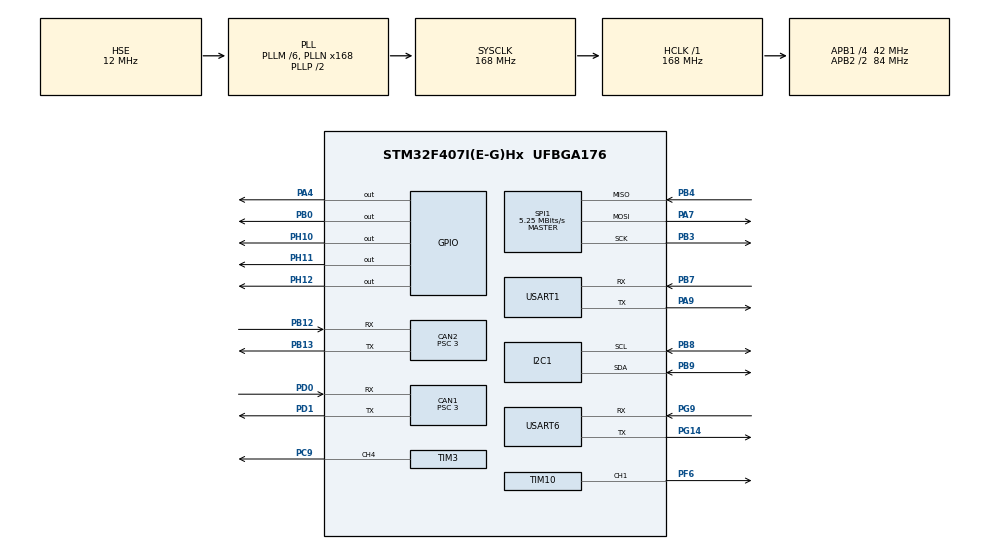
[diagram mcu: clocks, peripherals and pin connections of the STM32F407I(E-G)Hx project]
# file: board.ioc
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CAN1.ABOM=ENABLE
CAN1.BS1=CAN_BS1_10TQ
CAN1.BS2=CAN_BS2_3TQ
CAN1.CalculateBaudRate=1000000
CAN1.CalculateTimeBit=1000
CAN1.CalculateTimeQuantum=71.42857142857143
CAN1.Prescaler=3
CAN2.ABOM=ENABLE
CAN2.BS1=CAN_BS1_10TQ
CAN2.BS2=CAN_BS2_3TQ
CAN2.CalculateBaudRate=1000000
CAN2.CalculateTimeBit=1000
CAN2.CalculateTimeQuantum=71.42857142857143
CAN2.Prescaler=3
Dma.Request0=USART1_RX
Dma.Request1=USART1_TX
Dma.Request2=USART6_RX
Dma.Request3=USART6_TX
Dma.USART1_RX.0.Direction=DMA_PERIPH_TO_MEMORY
Dma.USART1_RX.0.FIFOMode=DMA_FIFOMODE_DISABLE
Dma.USART1_RX.0.Instance=DMA2_Stream2
Dma.USART1_RX.0.MemDataAlignment=DMA_MDATAALIGN_BYTE
Dma.USART1_RX.0.MemInc=DMA_MINC_ENABLE
Dma.USART1_RX.0.Mode=DMA_CIRCULAR
Dma.USART1_RX.0.PeriphDataAlignment=DMA_PDATAALIGN_BYTE
Dma.USART1_RX.0.PeriphInc=DMA_PINC_DISABLE
Dma.USART1_RX.0.Priority=DMA_PRIORITY_LOW
Dma.USART1_TX.1.Direction=DMA_MEMORY_TO_PERIPH
Dma.USART1_TX.1.FIFOMode=DMA_FIFOMODE_DISABLE
Dma.USART1_TX.1.Instance=DMA2_Stream7
Dma.USART1_TX.1.MemDataAlignment=DMA_MDATAALIGN_BYTE
Dma.USART1_TX.1.MemInc=DMA_MINC_ENABLE
Dma.USART1_TX.1.Mode=DMA_NORMAL
Dma.USART1_TX.1.PeriphDataAlignment=DMA_PDATAALIGN_BYTE
Dma.USART1_TX.1.PeriphInc=DMA_PINC_DISABLE
Dma.USART1_TX.1.Priority=DMA_PRIORITY_LOW
Dma.USART6_RX.2.Direction=DMA_PERIPH_TO_MEMORY
Dma.USART6_RX.2.FIFOMode=DMA_FIFOMODE_DISABLE
Dma.USART6_RX.2.Instance=DMA2_Stream1
Dma.USART6_RX.2.MemDataAlignment=DMA_MDATAALIGN_BYTE
Dma.USART6_RX.2.MemInc=DMA_MINC_ENABLE
Dma.USART6_RX.2.Mode=DMA_CIRCULAR
Dma.USART6_RX.2.PeriphDataAlignment=DMA_PDATAALIGN_BYTE
Dma.USART6_RX.2.PeriphInc=DMA_PINC_DISABLE
Dma.USART6_RX.2.Priority=DMA_PRIORITY_LOW
Dma.USART6_TX.3.Direction=DMA_MEMORY_TO_PERIPH
Dma.USART6_TX.3.FIFOMode=DMA_FIFOMODE_DISABLE
Dma.USART6_TX.3.Instance=DMA2_Stream6
Dma.USART6_TX.3.MemDataAlignment=DMA_MDATAALIGN_BYTE
Dma.USART6_TX.3.MemInc=DMA_MINC_ENABLE
Dma.USART6_TX.3.Mode=DMA_NORMAL
Dma.USART6_TX.3.PeriphDataAlignment=DMA_PDATAALIGN_BYTE
Dma.USART6_TX.3.PeriphInc=DMA_PINC_DISABLE
Dma.USART6_TX.3.Priority=DMA_PRIORITY_LOW
I2C1.I2C_Mode=I2C_Fast
Mcu.Family=STM32F4
Mcu.Name=STM32F407I(E-G)Hx
Mcu.Package=UFBGA176
NVIC.CAN1_RX0_IRQn=true\:0\:0\:false\:false\:true\:false\:true\:true\:true
NVIC.CAN2_RX0_IRQn=true\:0\:0\:false\:false\:true\:false\:true\:true\:true
NVIC.DMA2_Stream1_IRQn=true\:0\:0\:false\:false\:true\:true\:false\:true\:true
NVIC.DMA2_Stream2_IRQn=true\:0\:0\:false\:false\:true\:true\:false\:true\:true
NVIC.DMA2_Stream6_IRQn=true\:0\:0\:false\:false\:true\:true\:false\:true\:true
NVIC.DMA2_Stream7_IRQn=true\:0\:0\:false\:false\:true\:true\:false\:true\:true
NVIC.PriorityGroup=NVIC_PRIORITYGROUP_4
NVIC.TIM6_DAC_IRQn=true\:15\:0\:false\:false\:true\:false\:false\:true\:true
NVIC.TimeBase=TIM6_DAC_IRQn
NVIC.TimeBaseIP=TIM6
NVIC.USART1_IRQn=true\:6\:0\:true\:false\:true\:false\:true\:true\:true
NVIC.USART6_IRQn=true\:6\:0\:true\:false\:true\:false\:true\:true\:true
PA0-WKUP.Mode=SYS_WakeUp0
PA0-WKUP.Signal=SYS_WKUP
PA13.Mode=Serial_Wire
PA13.Signal=SYS_JTMS-SWDIO
PA14.Mode=Serial_Wire
PA14.Signal=SYS_JTCK-SWCLK
PA4.GPIO_Speed=GPIO_SPEED_FREQ_VERY_HIGH
PA4.PinState=GPIO_PIN_SET
PA4.Signal=GPIO_Output
PA7.Mode=Full_Duplex_Master
PA7.Signal=SPI1_MOSI
PA9.Mode=Asynchronous
PA9.Signal=USART1_TX
PB0.GPIO_PuPd=GPIO_NOPULL
PB0.GPIO_Speed=GPIO_SPEED_FREQ_VERY_HIGH
PB0.PinState=GPIO_PIN_SET
PB0.Signal=GPIO_Output
PB12.Mode=CAN_Activate
PB12.Signal=CAN2_RX
PB13.Mode=CAN_Activate
PB13.Signal=CAN2_TX
PB3.Mode=Full_Duplex_Master
PB3.Signal=SPI1_SCK
PB4.Mode=Full_Duplex_Master
PB4.Signal=SPI1_MISO
PB7.Mode=Asynchronous
PB7.Signal=USART1_RX
PB8.Mode=I2C
PB8.Signal=I2C1_SCL
PB9.Mode=I2C
PB9.Signal=I2C1_SDA
PC9.Signal=S_TIM3_CH4
PD0.Mode=CAN_Activate
PD0.Signal=CAN1_RX
PD1.Mode=CAN_Activate
PD1.Signal=CAN1_TX
PF6.Signal=S_TIM10_CH1
PG14.Mode=Asynchronous
PG14.Signal=USART6_TX
PG9.Mode=Asynchronous
PG9.Signal=USART6_RX
PH0-OSC_IN.Mode=HSE-External-Oscillator
PH0-OSC_IN.Signal=RCC_OSC_IN
PH1-OSC_OUT.Mode=HSE-External-Oscillator
PH1-OSC_OUT.Signal=RCC_OSC_OUT
PH10.PinState=GPIO_PIN_SET
PH10.Signal=GPIO_Output
PH11.PinState=GPIO_PIN_SET
PH11.Signal=GPIO_Output
PH12.Signal=GPIO_Output
ProjectManager.HeapSize=0x200
ProjectManager.StackSize=0x400
ProjectManager.TargetToolchain=CMake
RCC.48MHZClocksFreq_Value=84000000
RCC.AHBFreq_Value=168000000
RCC.APB1CLKDivider=RCC_HCLK_DIV4
RCC.APB1Freq_Value=42000000
RCC.APB1TimFreq_Value=84000000
RCC.APB2CLKDivider=RCC_HCLK_DIV2
RCC.APB2Freq_Value=84000000
RCC.APB2TimFreq_Value=168000000
RCC.CortexFreq_Value=168000000
RCC.HCLKFreq_Value=168000000
RCC.HSE_VALUE=12000000
RCC.HSI_VALUE=16000000
RCC.LSE_VALUE=32768
RCC.PLLM=6
RCC.PLLN=168
RCC.PLLSourceVirtual=RCC_PLLSOURCE_HSE
RCC.SYSCLKFreq_VALUE=168000000
RCC.SYSCLKSource=RCC_SYSCLKSOURCE_PLLCLK
RCC.VCOOutputFreq_Value=336000000
SH.S_TIM10_CH1.0=TIM10_CH1,PWM Generation1 CH1
SH.S_TIM3_CH4.0=TIM3_CH4,PWM Generation4 CH4
SPI1.BaudRatePrescaler=SPI_BAUDRATEPRESCALER_16
SPI1.CalculateBaudRate=5.25 MBits/s
SPI1.Direction=SPI_DIRECTION_2LINES
SPI1.Mode=SPI_MODE_MASTER
SPI1.VirtualType=VM_MASTER
STMicroelectronics.X-CUBE-AZRTOS-F4.1.1.0.TX_TIMER_TICKS_PER_SECOND=1000
STMicroelectronics.X-CUBE-AZRTOS-F4.1.1.0.ThreadXCcRTOSJjThreadXJjCore=true
STMicroelectronics.X-CUBE-AZRTOS-F4.1.1.0_IsAnAzureRtosMw=true
TIM10.Channel=TIM_CHANNEL_1
TIM10.Period=250-1
TIM10.Prescaler=168-1
TIM3.Channel-PWM\ Generation4\ CH4=TIM_CHANNEL_4
TIM3.Period=250-1
TIM3.Prescaler=84-1
USART1.VirtualMode=VM_ASYNC
USART6.VirtualMode=VM_ASYNC
VP_STMicroelectronics.X-CUBE-AZRTOS-F4_VS_RTOSJjThreadX_6.1.10_1.1.0.Mode=RTOSJjThreadX
VP_SYS_VS_tim6.Mode=TIM6
VP_TIM10_VS_ClockSourceINT.Mode=Enable_Timer
VP_TIM3_VS_ClockSourceINT.Mode=Internal
board=custom

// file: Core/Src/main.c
/* USER CODE BEGIN Header */
/**
  ******************************************************************************
  * @file           : main.c
  * @brief          : Main program body
  ******************************************************************************
  * @attention
  *
  * Copyright (c) 2026 STMicroelectronics.
  * All rights reserved.
  *
  * This software is licensed under terms that can be found in the LICENSE file
  * in the root directory of this software component.
  * If no LICENSE file comes with this software, it is provided AS-IS.
  *
  ******************************************************************************
  */
/* USER CODE END Header */
#include "app_threadx.h"
#include "main.h"
#include "can.h"
#include "dma.h"
#include "i2c.h"
#include "spi.h"
#include "tim.h"
#include "usart.h"
#include "gpio.h"

void SystemClock_Config(void);

int main(void)
{

  /* MCU Configuration--------------------------------------------------------*/

  /* Reset of all peripherals, Initializes the Flash interface and the Systick. */
  HAL_Init();

  /* Configure the system clock */
  SystemClock_Config();

  /* Initialize all configured peripherals */
  MX_GPIO_Init();
  MX_DMA_Init();
  MX_USART1_UART_Init();
  MX_USART6_UART_Init();
  MX_CAN1_Init();
  MX_CAN2_Init();
  MX_I2C1_Init();
  MX_SPI1_Init();
  MX_TIM3_Init();
  MX_TIM10_Init();

  MX_ThreadX_Init();

  /* We should never get here as control is now taken by the scheduler */

  /* Infinite loop */
  while (1)
  {

  }
}

void SystemClock_Config(void)
{
  RCC_OscInitTypeDef RCC_OscInitStruct = {0};
  RCC_ClkInitTypeDef RCC_ClkInitStruct = {0};

  /** Configure the main internal regulator output voltage
  */
  __HAL_RCC_PWR_CLK_ENABLE();
  __HAL_PWR_VOLTAGESCALING_CONFIG(PWR_REGULATOR_VOLTAGE_SCALE1);

  /** Initializes the RCC Oscillators according to the specified parameters
  * in the RCC_OscInitTypeDef structure.
  */
  RCC_OscInitStruct.OscillatorType = RCC_OSCILLATORTYPE_HSE;
  RCC_OscInitStruct.HSEState = RCC_HSE_ON;
  RCC_OscInitStruct.PLL.PLLState = RCC_PLL_ON;
  RCC_OscInitStruct.PLL.PLLSource = RCC_PLLSOURCE_HSE;
  RCC_OscInitStruct.PLL.PLLM = 6;
  RCC_OscInitStruct.PLL.PLLN = 168;
  RCC_OscInitStruct.PLL.PLLP = RCC_PLLP_DIV2;
  RCC_OscInitStruct.PLL.PLLQ = 4;
  if (HAL_RCC_OscConfig(&RCC_OscInitStruct) != HAL_OK)
  {
    Error_Handler();
  }

  /** Initializes the CPU, AHB and APB buses clocks
  */
  RCC_ClkInitStruct.ClockType = RCC_CLOCKTYPE_HCLK|RCC_CLOCKTYPE_SYSCLK
                              |RCC_CLOCKTYPE_PCLK1|RCC_CLOCKTYPE_PCLK2;
  RCC_ClkInitStruct.SYSCLKSource = RCC_SYSCLKSOURCE_PLLCLK;
  RCC_ClkInitStruct.AHBCLKDivider = RCC_SYSCLK_DIV1;
  RCC_ClkInitStruct.APB1CLKDivider = RCC_HCLK_DIV4;
  RCC_ClkInitStruct.APB2CLKDivider = RCC_HCLK_DIV2;

  if (HAL_RCC_ClockConfig(&RCC_ClkInitStruct, FLASH_LATENCY_5) != HAL_OK)
  {
    Error_Handler();
  }
}

void HAL_TIM_PeriodElapsedCallback(TIM_HandleTypeDef *htim)
{
  if (htim->Instance == TIM6)
  {
    HAL_IncTick();
  }
}

void Error_Handler(void)
{
  /* USER CODE BEGIN Error_Handler_Debug */
  /* User can add his own implementation to report the HAL error return state */
  __disable_irq();
  while (1)
  {
    HAL_GPIO_WritePin(GPIOH, GPIO_PIN_10, GPIO_PIN_RESET);
  }
  /* USER CODE END Error_Handler_Debug */
}
